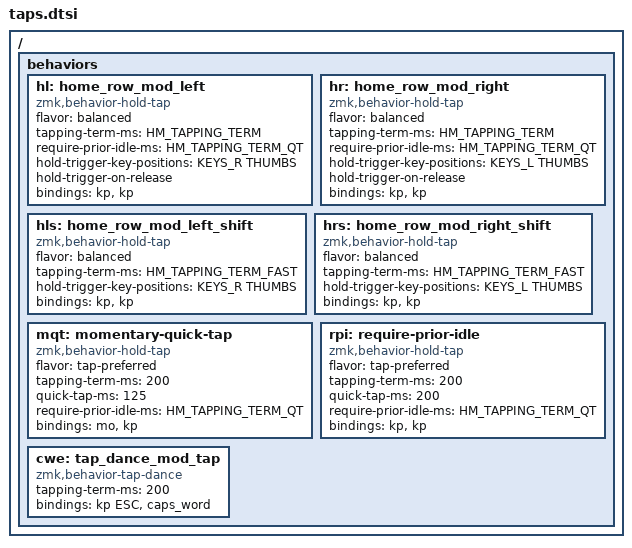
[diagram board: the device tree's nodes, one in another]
// #include "zmk-helpers/key-labels/42.h"

//  ╭─────────────────────────┬─────────────────────────╮
//  │ LT5 LT4 LT3 LT2 LT1 LT0 │ RT0 RT1 RT2 RT3 RT4 RT5 │
//  │ LM5 LM4 LM3 LM2 LM1 LM0 │ RM0 RM1 RM2 RM3 RM4 RM5 │
//  │ LB5 LB4 LB3 LB2 LB1 LB0 │ RB0 RB1 RB2 RB3 RB4 RB5 │
//  ╰───────────╮ LH2 LH1 LH0 │ RH0 RH1 RH2 ╭───────────╯
//              ╰─────────────┴─────────────╯            

#define KEYS_L LT5 LT4 LT3 LT2 LT1 LT0 LM5 LM4 LM3 LM2 LM1 LM0 LB5 LB4 LB3 LB2 LB1 LB0
#define KEYS_R RT0 RT1 RT2 RT3 RT4 RT5 RM0 RM1 RM2 RM3 RM4 RM5 RB0 RB1 RB2 RB3 RB4 RB5
#define THUMBS LH2 LH1 LH0 RH0 RH1 RH2

#define HM_TAPPING_TERM 280
#define HM_TAPPING_TERM_FAST 200
#define HM_TAPPING_TERM_QT 175

/ {
	behaviors {
		
		hl: home_row_mod_left {
			compatible = "zmk,behavior-hold-tap";
			#binding-cells = <2>;
			flavor = "balanced";
			tapping-term-ms = <HM_TAPPING_TERM>;
			require-prior-idle-ms = <HM_TAPPING_TERM_QT>;
			hold-trigger-key-positions = < KEYS_R THUMBS >;
			hold-trigger-on-release;
			bindings = <&kp>, <&kp>;
		};
		
		hr: home_row_mod_right {
			compatible = "zmk,behavior-hold-tap";
			#binding-cells = <2>;
			flavor = "balanced";
			tapping-term-ms = <HM_TAPPING_TERM>;
			require-prior-idle-ms = <HM_TAPPING_TERM_QT>;
			hold-trigger-key-positions = < KEYS_L THUMBS >;
			hold-trigger-on-release;
			bindings = <&kp>, <&kp>;
		};
		
		hls: home_row_mod_left_shift {
			compatible = "zmk,behavior-hold-tap";
			#binding-cells = <2>;
			flavor = "balanced";
			tapping-term-ms = <HM_TAPPING_TERM_FAST>;
			hold-trigger-key-positions = < KEYS_R THUMBS >;
			bindings = <&kp>, <&kp>;
		};
		
		hrs: home_row_mod_right_shift {
			compatible = "zmk,behavior-hold-tap";
			#binding-cells = <2>;
			flavor = "balanced";
			tapping-term-ms = <HM_TAPPING_TERM_FAST>;
			hold-trigger-key-positions = < KEYS_L THUMBS >;
			bindings = <&kp>, <&kp>;
		};
		
		mqt: momentary-quick-tap {
			compatible = "zmk,behavior-hold-tap";
			#binding-cells = <2>;
			flavor = "tap-preferred";
			tapping-term-ms = <200>;
			quick-tap-ms = <125>;
			require-prior-idle-ms = <HM_TAPPING_TERM_QT>;
			bindings = <&mo>, <&kp>;
		};
		
		rpi: require-prior-idle {
			compatible = "zmk,behavior-hold-tap";
			#binding-cells = <2>;
			flavor = "tap-preferred";
			tapping-term-ms = <200>;
			quick-tap-ms = <200>;	
			require-prior-idle-ms = <HM_TAPPING_TERM_QT>;
			bindings = <&kp>, <&kp>;
		};

		cwe: tap_dance_mod_tap {
			compatible = "zmk,behavior-tap-dance";
			#binding-cells = <0>;
			tapping-term-ms = <200>;
			bindings = <&kp ESC>, <&caps_word>;
		};
	};
};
